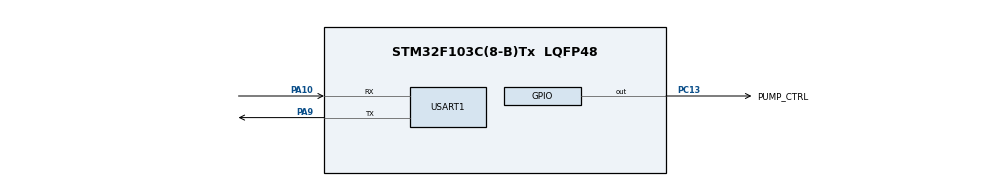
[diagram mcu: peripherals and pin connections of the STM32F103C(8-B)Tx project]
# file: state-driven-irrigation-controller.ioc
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Mcu.Family=STM32F1
Mcu.Name=STM32F103C(8-B)Tx
Mcu.Package=LQFP48
NVIC.PriorityGroup=NVIC_PRIORITYGROUP_4
PA10.Mode=Asynchronous
PA10.Signal=USART1_RX
PA9.Mode=Asynchronous
PA9.Signal=USART1_TX
PC13-TAMPER-RTC.GPIO_Label=PUMP_CTRL
PC13-TAMPER-RTC.GPIO_PuPd=GPIO_NOPULL
PC13-TAMPER-RTC.Signal=GPIO_Output
ProjectManager.HeapSize=0x200
ProjectManager.StackSize=0x400
ProjectManager.TargetToolchain=STM32CubeIDE
RCC.APB1Freq_Value=8000000
RCC.APB2Freq_Value=8000000
USART1.VirtualMode=VM_ASYNC
VP_SYS_VS_ND.Mode=No_Debug
board=custom

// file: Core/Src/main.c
/* USER CODE BEGIN Header */
/**
  ******************************************************************************
  * @file           : main.c
  * @brief          : Main program body
  ******************************************************************************
  * @attention
  *
  * Copyright (c) 2026 STMicroelectronics.
  * All rights reserved.
  *
  * This software is licensed under terms that can be found in the LICENSE file
  * in the root directory of this software component.
  * If no LICENSE file comes with this software, it is provided AS-IS.
  *
  ******************************************************************************
  */
/* USER CODE END Header */
#include "main.h"
#include <string.h>
#include <stdio.h>
#include "system_state.h"
#include "soil_sensor.h"
#include "logger.h"
#include "pump_control.h"
#include "config.h"

 UART_HandleTypeDef huart1;

/*global variable*/

uint32_t last_measure_time = 0;

uint32_t watering_start_time= 0;

uint16_t moisture_before_watering = 0;

void SystemClock_Config(void);
static void MX_GPIO_Init(void);
static void MX_USART1_UART_Init(void);

int main(void)
{

  /* MCU Configuration--------------------------------------------------------*/

  /* Reset of all peripherals, Initializes the Flash interface and the Systick. */
  HAL_Init();

  /* Configure the system clock */
  SystemClock_Config();

  /* Initialize all configured peripherals */
  MX_GPIO_Init();
  MX_USART1_UART_Init();
  logger_log("[BOOT] State_Driven Irrigation Controller started\r\n");
  system_state_set(STATE_INIT);
  logger_log("[STATE] INIT\n");

  /* Infinite loop */
  /* USER CODE BEGIN WHILE */
  while (1)
  {
	  uint32_t current_time = HAL_GetTick();
	  if ((current_time - last_measure_time) >= MEASURE_INTERVAL_MS)
	  {
		  last_measure_time = current_time;
		  system_state_t state = system_state_get();
		  switch (state)
		  {
		  case STATE_INIT:
			  logger_log("[STATE] INIT -> IDLE \n " );
			  system_state_set(STATE_IDLE);
			  break;

		  case STATE_IDLE:
			  logger_log("[STATE] IDLE -> MEASURING\n");
			  system_state_set(STATE_MEASURING);
			  break;

		  case STATE_MEASURING:
		  {
			  uint16_t moisture = soil_sensor_read();
			  char buf[50];
			  sprintf(buf, "[MEASURE] Moisture = %u \n", moisture);
			  logger_log(buf);

			  if (moisture < MOISTURE_DRY_THRESHOLD)
			  {
				  moisture_before_watering = moisture;
				  logger_log("[DECISION] Soil dry -> WATERING \n");
				  system_state_set(STATE_WATERING);

			  }
			  else
			  {
				  logger_log("[DECISION] Soil OK -> IDLE\n");
				  system_state_set(STATE_IDLE);

			  }
			  break;

		  }
		  case STATE_WATERING:
		  {
			  logger_log("[PUMP] ON\n");
			  pump_on();

			  watering_start_time = HAL_GetTick();
			  system_state_set(STATE_COOLDOWN);
			  break;

		  }
		  case STATE_COOLDOWN:
		  {
			  if((HAL_GetTick() - watering_start_time) >= WATERING_DURATION_MS)

			  {
				  pump_off();
				  logger_log("[PUMP] OFF\n");
				  soil_sensor_on_watering();

				  uint16_t moisture_after = soil_sensor_read();

				  if ((moisture_after - moisture_before_watering) < MOISTURE_MIN_IMPROVEMENT)
				  {
					  logger_log("[ERROR] Moisture did not improve after watering\n");
							  system_state_set(STATE_ERROR);
				  }
				  logger_log("[STATE] COOLDOWN -> IDLE\n");
				  system_state_set(STATE_IDLE);

			  }
			  break;

		  }

		  case STATE_ERROR:
		  {
			  pump_off();
			  logger_log("[STATE] ERROR - system halted\n");
			  break;
		  }

		  default:
			  break;

		  }
	  }

  }
}

void SystemClock_Config(void)
{
  RCC_OscInitTypeDef RCC_OscInitStruct = {0};
  RCC_ClkInitTypeDef RCC_ClkInitStruct = {0};

  /** Initializes the RCC Oscillators according to the specified parameters
  * in the RCC_OscInitTypeDef structure.
  */
  RCC_OscInitStruct.OscillatorType = RCC_OSCILLATORTYPE_HSI;
  RCC_OscInitStruct.HSIState = RCC_HSI_ON;
  RCC_OscInitStruct.HSICalibrationValue = RCC_HSICALIBRATION_DEFAULT;
  RCC_OscInitStruct.PLL.PLLState = RCC_PLL_NONE;
  if (HAL_RCC_OscConfig(&RCC_OscInitStruct) != HAL_OK)
  {
    Error_Handler();
  }

  /** Initializes the CPU, AHB and APB buses clocks
  */
  RCC_ClkInitStruct.ClockType = RCC_CLOCKTYPE_HCLK|RCC_CLOCKTYPE_SYSCLK
                              |RCC_CLOCKTYPE_PCLK1|RCC_CLOCKTYPE_PCLK2;
  RCC_ClkInitStruct.SYSCLKSource = RCC_SYSCLKSOURCE_HSI;
  RCC_ClkInitStruct.AHBCLKDivider = RCC_SYSCLK_DIV1;
  RCC_ClkInitStruct.APB1CLKDivider = RCC_HCLK_DIV1;
  RCC_ClkInitStruct.APB2CLKDivider = RCC_HCLK_DIV1;

  if (HAL_RCC_ClockConfig(&RCC_ClkInitStruct, FLASH_LATENCY_0) != HAL_OK)
  {
    Error_Handler();
  }
}

static void MX_USART1_UART_Init(void)
{

  huart1.Instance = USART1;
  huart1.Init.BaudRate = 115200;
  huart1.Init.WordLength = UART_WORDLENGTH_8B;
  huart1.Init.StopBits = UART_STOPBITS_1;
  huart1.Init.Parity = UART_PARITY_NONE;
  huart1.Init.Mode = UART_MODE_TX_RX;
  huart1.Init.HwFlowCtl = UART_HWCONTROL_NONE;
  huart1.Init.OverSampling = UART_OVERSAMPLING_16;
  if (HAL_UART_Init(&huart1) != HAL_OK)
  {
    Error_Handler();
  }

}

static void MX_GPIO_Init(void)
{
  GPIO_InitTypeDef GPIO_InitStruct = {0};

  /* GPIO Ports Clock Enable */
  __HAL_RCC_GPIOC_CLK_ENABLE();
  __HAL_RCC_GPIOA_CLK_ENABLE();

  /*Configure GPIO pin Output Level */
  HAL_GPIO_WritePin(PUMP_CTRL_GPIO_Port, PUMP_CTRL_Pin, GPIO_PIN_RESET);

  /*Configure GPIO pin : PUMP_CTRL_Pin */
  GPIO_InitStruct.Pin = PUMP_CTRL_Pin;
  GPIO_InitStruct.Mode = GPIO_MODE_OUTPUT_PP;
  GPIO_InitStruct.Pull = GPIO_NOPULL;
  GPIO_InitStruct.Speed = GPIO_SPEED_FREQ_LOW;
  HAL_GPIO_Init(PUMP_CTRL_GPIO_Port, &GPIO_InitStruct);

}

void Error_Handler(void)
{
  /* USER CODE BEGIN Error_Handler_Debug */
  /* User can add his own implementation to report the HAL error return state */
  __disable_irq();
  while (1)
  {
	 if (system_state_get () == STATE_IDLE)
	 {
		 soil_sensor_decay();
	 }

  }
  /* USER CODE END Error_Handler_Debug */
}
